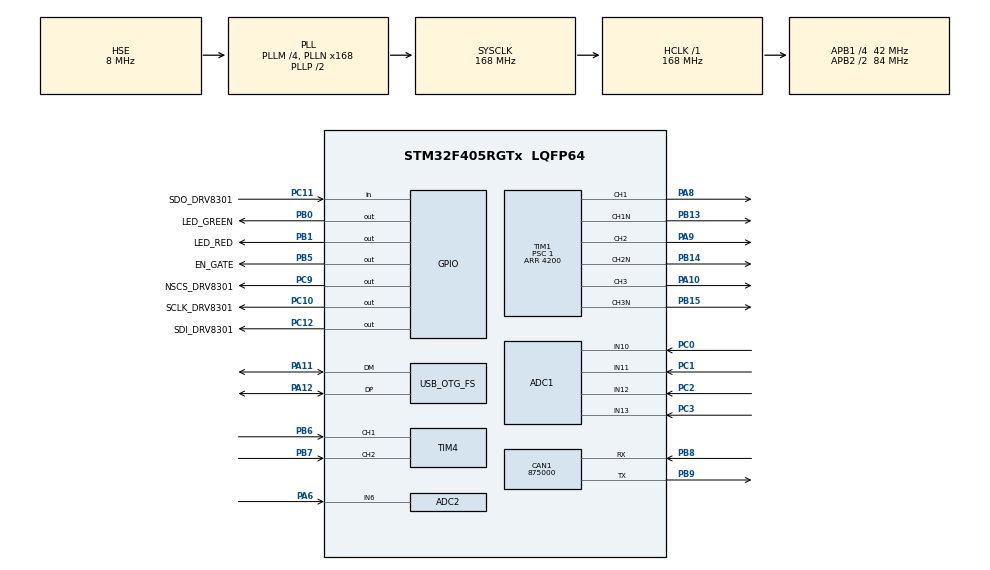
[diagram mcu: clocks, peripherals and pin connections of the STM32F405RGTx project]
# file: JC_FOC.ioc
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ADC1.Channel-2\#ChannelRegularConversion=ADC_CHANNEL_13
ADC1.Channel-3\#ChannelInjectedConversion=ADC_CHANNEL_10
ADC1.Channel-4\#ChannelInjectedConversion=ADC_CHANNEL_11
ADC1.Channel-5\#ChannelInjectedConversion=ADC_CHANNEL_12
ADC1.ContinuousConvMode=DISABLE
ADC1.ExternalTrigInjecConv=ADC_EXTERNALTRIGINJECCONV_T1_CC4
ADC1.ExternalTrigInjecConvEdge=ADC_EXTERNALTRIGINJECCONVEDGE_RISINGFALLING
ADC1.InjNumberOfConversion=3
ADC1.InjectedOffset-3\#ChannelInjectedConversion=0
ADC1.InjectedOffset-4\#ChannelInjectedConversion=0
ADC1.InjectedOffset-5\#ChannelInjectedConversion=0
ADC1.InjectedRank-3\#ChannelInjectedConversion=1
ADC1.InjectedRank-4\#ChannelInjectedConversion=2
ADC1.InjectedRank-5\#ChannelInjectedConversion=3
ADC1.NbrOfConversion=1
ADC1.NbrOfConversionFlag=1
ADC1.Rank-2\#ChannelRegularConversion=1
ADC1.SamplingTime-2\#ChannelRegularConversion=ADC_SAMPLETIME_3CYCLES
ADC1.SamplingTime-3\#ChannelInjectedConversion=ADC_SAMPLETIME_15CYCLES
ADC1.SamplingTime-4\#ChannelInjectedConversion=ADC_SAMPLETIME_15CYCLES
ADC1.SamplingTime-5\#ChannelInjectedConversion=ADC_SAMPLETIME_15CYCLES
ADC1.ScanConvMode=ENABLE
ADC1.master=1
ADC2.Channel-0\#ChannelRegularConversion=ADC_CHANNEL_6
ADC2.NbrOfConversionFlag=1
ADC2.Rank-0\#ChannelRegularConversion=1
ADC2.SamplingTime-0\#ChannelRegularConversion=ADC_SAMPLETIME_3CYCLES
CAN1.CalculateBaudRate=875000
CAN1.CalculateTimeBit=1142
CAN1.CalculateTimeQuantum=380.95238095238096
Mcu.Family=STM32F4
Mcu.Name=STM32F405RGTx
Mcu.Package=LQFP64
NVIC.ADC_IRQn=true\:0\:0\:true\:false\:true\:true\:true\:true
NVIC.OTG_FS_IRQn=true\:0\:0\:false\:false\:true\:false\:true\:true
NVIC.PriorityGroup=NVIC_PRIORITYGROUP_4
PA10.Signal=S_TIM1_CH3
PA11.Mode=Device_Only
PA11.Signal=USB_OTG_FS_DM
PA12.Mode=Device_Only
PA12.Signal=USB_OTG_FS_DP
PA13.Mode=Serial_Wire
PA13.Signal=SYS_JTMS-SWDIO
PA14.Mode=Serial_Wire
PA14.Signal=SYS_JTCK-SWCLK
PA6.Signal=ADCx_IN6
PA8.Signal=S_TIM1_CH1
PA9.Signal=S_TIM1_CH2
PB0.GPIO_Label=LED_GREEN
PB0.PinState=GPIO_PIN_RESET
PB0.Signal=GPIO_Output
PB1.GPIO_Label=LED_RED
PB1.PinState=GPIO_PIN_SET
PB1.Signal=GPIO_Output
PB13.Mode=PWM Generation1 CH1 CH1N
PB13.Signal=TIM1_CH1N
PB14.Mode=PWM Generation2 CH2 CH2N
PB14.Signal=TIM1_CH2N
PB15.Mode=PWM Generation3 CH3 CH3N
PB15.Signal=TIM1_CH3N
PB5.GPIO_Label=EN_GATE
PB5.GPIO_Speed=GPIO_SPEED_FREQ_HIGH
PB5.Signal=GPIO_Output
PB6.Signal=S_TIM4_CH1
PB7.Signal=S_TIM4_CH2
PB8.Mode=CAN_Activate
PB8.Signal=CAN1_RX
PB9.Mode=CAN_Activate
PB9.Signal=CAN1_TX
PC0.Signal=ADCx_IN10
PC1.Signal=ADCx_IN11
PC10.GPIO_Label=SCLK_DRV8301
PC10.GPIO_Speed=GPIO_SPEED_FREQ_VERY_HIGH
PC10.PinState=GPIO_PIN_RESET
PC10.Signal=GPIO_Output
PC11.GPIO_Label=SDO_DRV8301
PC11.Signal=GPIO_Input
PC12.GPIO_Label=SDI_DRV8301
PC12.GPIO_Speed=GPIO_SPEED_FREQ_VERY_HIGH
PC12.Signal=GPIO_Output
PC2.Signal=ADCx_IN12
PC3.Signal=ADCx_IN13
PC9.GPIO_Label=NSCS_DRV8301
PC9.GPIO_Speed=GPIO_SPEED_FREQ_VERY_HIGH
PC9.PinState=GPIO_PIN_SET
PC9.Signal=GPIO_Output
PH0-OSC_IN.Mode=HSE-External-Oscillator
PH0-OSC_IN.Signal=RCC_OSC_IN
PH1-OSC_OUT.Mode=HSE-External-Oscillator
PH1-OSC_OUT.Signal=RCC_OSC_OUT
ProjectManager.HeapSize=0x400
ProjectManager.StackSize=0x800
ProjectManager.TargetToolchain=MDK-ARM V5.32
RCC.48MHZClocksFreq_Value=48000000
RCC.AHBFreq_Value=168000000
RCC.APB1CLKDivider=RCC_HCLK_DIV4
RCC.APB1Freq_Value=42000000
RCC.APB1TimFreq_Value=84000000
RCC.APB2CLKDivider=RCC_HCLK_DIV2
RCC.APB2Freq_Value=84000000
RCC.APB2TimFreq_Value=168000000
RCC.CortexFreq_Value=168000000
RCC.HCLKFreq_Value=168000000
RCC.HSE_VALUE=8000000
RCC.HSI_VALUE=16000000
RCC.LSE_VALUE=32768
RCC.PLLM=4
RCC.PLLN=168
RCC.PLLQ=7
RCC.SYSCLKFreq_VALUE=168000000
RCC.SYSCLKSource=RCC_SYSCLKSOURCE_PLLCLK
RCC.VCOOutputFreq_Value=336000000
SH.ADCx_IN10.0=ADC1_IN10,IN10
SH.ADCx_IN11.0=ADC1_IN11,IN11
SH.ADCx_IN12.0=ADC1_IN12,IN12
SH.ADCx_IN13.0=ADC1_IN13,IN13
SH.ADCx_IN6.0=ADC2_IN6,IN6
SH.S_TIM1_CH1.0=TIM1_CH1,PWM Generation1 CH1 CH1N
SH.S_TIM1_CH2.0=TIM1_CH2,PWM Generation2 CH2 CH2N
SH.S_TIM1_CH3.0=TIM1_CH3,PWM Generation3 CH3 CH3N
SH.S_TIM4_CH1.0=TIM4_CH1,Encoder_Interface
SH.S_TIM4_CH2.0=TIM4_CH2,Encoder_Interface
TIM1.Channel-PWM\ Generation1\ CH1\ CH1N=TIM_CHANNEL_1
TIM1.Channel-PWM\ Generation2\ CH2\ CH2N=TIM_CHANNEL_2
TIM1.Channel-PWM\ Generation3\ CH3\ CH3N=TIM_CHANNEL_3
TIM1.Channel-PWM\ Generation4\ No\ Output=TIM_CHANNEL_4
TIM1.CounterMode=TIM_COUNTERMODE_CENTERALIGNED1
TIM1.DeadTime=168
TIM1.Period=4200
TIM1.Prescaler=1
TIM1.Pulse-PWM\ Generation4\ No\ Output=1300
USB_DEVICE.CLASS_NAME_FS=CDC
USB_DEVICE.VirtualMode-CDC_FS=Cdc
USB_DEVICE.VirtualModeFS=Cdc_FS
USB_OTG_FS.VirtualMode=Device_Only
VP_TIM1_VS_ClockSourceINT.Mode=Internal
VP_TIM1_VS_no_output4.Mode=PWM Generation4 No Output
VP_USB_DEVICE_VS_USB_DEVICE_CDC_FS.Mode=CDC_FS
board=custom

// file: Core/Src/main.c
/* USER CODE BEGIN Header */
/**
 ******************************************************************************
 * @file           : main.c
 * @brief          : Main program body
 ******************************************************************************
 * @attention
 *
 * Copyright (c) 2024 STMicroelectronics.
 * All rights reserved.
 *
 * This software is licensed under terms that can be found in the LICENSE file
 * in the root directory of this software component.
 * If no LICENSE file comes with this software, it is provided AS-IS.
 *
 ******************************************************************************
 */
/* USER CODE END Header */
#include "main.h"
#include "adc.h"
#include "can.h"
#include "tim.h"
#include "usb_device.h"
#include "gpio.h"

/* USER CODE BEGIN Includes */
#include "APPMain.h"
//#include "vofa.h"
/* USER CODE END Includes */

void SystemClock_Config(void);
/* USER CODE BEGIN PFP */

float ADCbuffer[3];
void HAL_ADCEx_InjectedConvCpltCallback(ADC_HandleTypeDef *hadc)
{

  ADCbuffer[0] = hadc1.Instance->JDR1;
  ADCbuffer[1] = hadc1.Instance->JDR2;
  ADCbuffer[2] = hadc1.Instance->JDR3;

  static uint16_t test = 0;
  if (test++ > 65530)
    test = 0;

  //	HAL_Delay(1000);

  //    HAL_ADCEx_InjectedStart_IT(&hadc1);
}
/* USER CODE END PFP */

int main(void)
{

  /* MCU Configuration--------------------------------------------------------*/

  /* Reset of all peripherals, Initializes the Flash interface and the Systick. */
  HAL_Init();

  /* Configure the system clock */
  SystemClock_Config();

  /* Initialize all configured peripherals */
  MX_GPIO_Init();
  MX_USB_DEVICE_Init();
  MX_ADC1_Init();
  MX_TIM1_Init();
  MX_CAN1_Init();
  MX_ADC2_Init();
  MX_TIM4_Init();
  /* USER CODE BEGIN 2 */

   APPMain_Init();

  HAL_TIM_PWM_Start(&htim1, TIM_CHANNEL_4);
  __HAL_TIM_SET_COMPARE(&htim1, TIM_CHANNEL_4, 1300); // 4800为最大占空比
                                                      //  HAL_ADCEx_InjectedStart(&hadc1);

  HAL_ADCEx_InjectedStart_IT(&hadc1);
  /* USER CODE END 2 */

  /* Infinite loop */
  /* USER CODE BEGIN WHILE */

  while (1)
  {

	    // APPMain_Loop();
    /* USER CODE END WHILE */

    /* USER CODE BEGIN 3 */
//       HAL_GPIO_TogglePin(LED_RED_GPIO_Port, LED_RED_Pin);
//       HAL_Delay(1000);

//    Vofa_JustFloat(ADCbuffer, 3);
  }
  /* USER CODE END 3 */
}

void SystemClock_Config(void)
{
  RCC_OscInitTypeDef RCC_OscInitStruct = {0};
  RCC_ClkInitTypeDef RCC_ClkInitStruct = {0};

  /** Configure the main internal regulator output voltage
  */
  __HAL_RCC_PWR_CLK_ENABLE();
  __HAL_PWR_VOLTAGESCALING_CONFIG(PWR_REGULATOR_VOLTAGE_SCALE1);

  /** Initializes the RCC Oscillators according to the specified parameters
  * in the RCC_OscInitTypeDef structure.
  */
  RCC_OscInitStruct.OscillatorType = RCC_OSCILLATORTYPE_HSE;
  RCC_OscInitStruct.HSEState = RCC_HSE_ON;
  RCC_OscInitStruct.PLL.PLLState = RCC_PLL_ON;
  RCC_OscInitStruct.PLL.PLLSource = RCC_PLLSOURCE_HSE;
  RCC_OscInitStruct.PLL.PLLM = 4;
  RCC_OscInitStruct.PLL.PLLN = 168;
  RCC_OscInitStruct.PLL.PLLP = RCC_PLLP_DIV2;
  RCC_OscInitStruct.PLL.PLLQ = 7;
  if (HAL_RCC_OscConfig(&RCC_OscInitStruct) != HAL_OK)
  {
    Error_Handler();
  }

  /** Initializes the CPU, AHB and APB buses clocks
  */
  RCC_ClkInitStruct.ClockType = RCC_CLOCKTYPE_HCLK|RCC_CLOCKTYPE_SYSCLK
                              |RCC_CLOCKTYPE_PCLK1|RCC_CLOCKTYPE_PCLK2;
  RCC_ClkInitStruct.SYSCLKSource = RCC_SYSCLKSOURCE_PLLCLK;
  RCC_ClkInitStruct.AHBCLKDivider = RCC_SYSCLK_DIV1;
  RCC_ClkInitStruct.APB1CLKDivider = RCC_HCLK_DIV4;
  RCC_ClkInitStruct.APB2CLKDivider = RCC_HCLK_DIV2;

  if (HAL_RCC_ClockConfig(&RCC_ClkInitStruct, FLASH_LATENCY_5) != HAL_OK)
  {
    Error_Handler();
  }
}

void Error_Handler(void)
{
  __disable_irq();
  while (1)
  {
  }
}
